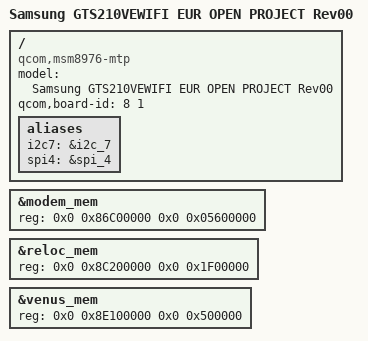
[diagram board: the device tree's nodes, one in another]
/*
 * Copyright (c) 2015, The Linux Foundation. All rights reserved.
 *
 * This program is free software; you can redistribute it and/or modify
 * it under the terms of the GNU General Public License version 2 and
 * only version 2 as published by the Free Software Foundation.
 *
 * This program is distributed in the hope that it will be useful,
 * but WITHOUT ANY WARRANTY; without even the implied warranty of
 * MERCHANTABILITY or FITNESS FOR A PARTICULAR PURPOSE.  See the
 * GNU General Public License for more details.
 */

/dts-v1/;

#include "msm8976-sec-gts210vewifi-eur-r00.dtsi"

&modem_mem{
	reg = <0x0 0x86C00000 0x0 0x05600000>;
};

&reloc_mem{
	reg = <0x0 0x8C200000 0x0 0x1F00000>;
};

&venus_mem {
	reg = <0x0 0x8E100000 0x0 0x500000>;
};

/ {
	model = "Samsung GTS210VEWIFI EUR OPEN PROJECT Rev00";
	compatible = "qcom,msm8976-mtp", "qcom,msm8976", "qcom,mtp";
	qcom,board-id= <8 1>;

	aliases {
		i2c7 = &i2c_7;
		spi4 = &spi_4;
	};
};
